AUTOSAR XML (schema 4-1-3)
standard types defined: boolean, sint8, uint16, uint32, uint8, boolean_CompuMethod, boolean_DataConstr, sint8_DataConstr, uint16_DataConstr, uint32_DataConstr, uint8_DataConstr
package /MICROSAR/Dem_swc/DataTypes
  5 x impl type:
    Dem_DebounceResetStatusType: compu {0=DEM_DEBOUNCE_STATUS_FREEZE, 1=DEM_DEBOUNCE_STATUS_RESET}, range raw 0..255, implementation-data-type=ImplementationDataTypes/uint8
    Dem_DTCFormatType: compu {0=DEM_DTC_FORMAT_OBD, 1=DEM_DTC_FORMAT_UDS, 2=DEM_DTC_FORMAT_J1939}, range raw 0..255, implementation-data-type=ImplementationDataTypes/uint8
    Dem_EventStatusType:
      compu {0=DEM_EVENT_STATUS_PASSED, 1=DEM_EVENT_STATUS_FAILED, 2=DEM_EVENT_STATUS_PREPASSED, 3=DEM_EVENT_STATUS_PREFAILED, 4=DEM_EVENT_STATUS_FDC_THRESHOLD_REACHED, 5=DEM_EVENT_STATUS_PASSED_CONDITIONS_NOT_FULFILLED, 6=DEM_EVENT_STATUS_FAILED_CONDITIONS_NOT_FULFILLED, 7=DEM_EVENT_STATUS_PREPASSED_CONDITIONS_NOT_FULFILLED, 8=DEM_EVENT_STATUS_PREFAILED_CONDITIONS_NOT_FULFILLED}
      range raw 0..255
      implementation-data-type=ImplementationDataTypes/uint8
    Dem_MaxDataValueType: category=ARRAY, sw-calibration-access=READ-ONLY
      element Dem_MaxDataValueTypeElement: array-size=4, array-size-semantics=FIXED-SIZE, implementation-data-type=ImplementationDataTypes/uint8
    Dem_UdsStatusByteType:
      compu {mask 1: 1=DEM_UDS_STATUS_TF (bit 0: TestFailed), mask 2: 2=DEM_UDS_STATUS_TFTOC (bit 1: TestFailedThisOperationCycle), mask 4: 4=DEM_UDS_STATUS_PDTC (bit 2: PendingDTC), mask 8: 8=DEM_UDS_STATUS_CDTC (bit 3: ConfirmedDTC), mask 16: 16=DEM_UDS_STATUS_TNCSLC (bit 4: TestNotCompletedSinceLastClear), mask 32: 32=DEM_UDS_STATUS_TFSLC (bit 5: TestFailedSinceLastClear), mask 64: 64=DEM_UDS_STATUS_TNCTOC (bit 6: TestNotCompletedThisOperationCycle), mask 128: 128=DEM_UDS_STATUS_WIR (bit 7: WarningIndicatorRequested)}
      range raw 0..255
      implementation-data-type=ImplementationDataTypes/uint8
package /MICROSAR/Dem_swc/Interfaces
  client server interface DiagnosticMonitor: is-service=true, service-kind=DIAGNOSTIC-EVENT-MANAGER
    11 x operation:
      GetDTCOfEvent: possible-error=[DEM_E_NO_DTC_AVAILABLE, DiagnosticMonitor/E_NOT_OK]
        arg DTCFormat: type=Dem_DTCFormatType, direction=IN, server-argument-impl-policy=USE-ARGUMENT-TYPE
        arg DTCOfEvent: type=ImplementationDataTypes/uint32, direction=OUT, server-argument-impl-policy=USE-ARGUMENT-TYPE
      GetEventExtendedDataRecordEx: possible-error=[DEM_BUFFER_TOO_SMALL, DEM_NO_SUCH_ELEMENT, DiagnosticMonitor/E_NOT_OK]
        arg RecordNumber: type=ImplementationDataTypes/uint8, direction=IN, server-argument-impl-policy=USE-ARGUMENT-TYPE
        arg DestBuffer: type=Dem_MaxDataValueType, direction=OUT, server-argument-impl-policy=USE-ARGUMENT-TYPE
        arg BufSize: type=ImplementationDataTypes/uint16, direction=INOUT, server-argument-impl-policy=USE-ARGUMENT-TYPE
      GetEventFailed: possible-error=DiagnosticMonitor/E_NOT_OK
        arg EventFailed: type=ImplementationDataTypes/boolean, direction=OUT, server-argument-impl-policy=USE-ARGUMENT-TYPE
      GetEventFreezeFrameDataEx: possible-error=[DEM_BUFFER_TOO_SMALL, DEM_NO_SUCH_ELEMENT, DiagnosticMonitor/E_NOT_OK]
        4 x arg, all with server-argument-impl-policy=USE-ARGUMENT-TYPE:
          RecordNumber: type=ImplementationDataTypes/uint8, direction=IN
          DataId: type=ImplementationDataTypes/uint16, direction=IN
          DestBuffer: type=Dem_MaxDataValueType, direction=OUT
          BufSize: type=ImplementationDataTypes/uint16, direction=INOUT
      GetEventStatus: possible-error=DiagnosticMonitor/E_NOT_OK
        arg UDSStatusByte: type=Dem_UdsStatusByteType, direction=OUT, server-argument-impl-policy=USE-ARGUMENT-TYPE
      GetEventTested: possible-error=DiagnosticMonitor/E_NOT_OK
        arg EventTested: type=ImplementationDataTypes/boolean, direction=OUT, server-argument-impl-policy=USE-ARGUMENT-TYPE
      GetEventUdsStatus: possible-error=DiagnosticMonitor/E_NOT_OK
        arg UDSStatusByte: type=Dem_UdsStatusByteType, direction=OUT, server-argument-impl-policy=USE-ARGUMENT-TYPE
      GetFaultDetectionCounter: possible-error=[DEM_E_NO_FDC_AVAILABLE, DiagnosticMonitor/E_NOT_OK]
        arg FaultDetectionCounter: type=sint8, direction=OUT, server-argument-impl-policy=USE-ARGUMENT-TYPE
      ResetEventDebounceStatus: possible-error=DiagnosticMonitor/E_NOT_OK
        arg DebounceResetStatus: type=Dem_DebounceResetStatusType, direction=IN, server-argument-impl-policy=USE-ARGUMENT-TYPE
      ResetEventStatus: possible-error=DiagnosticMonitor/E_NOT_OK
      SetEventStatus: possible-error=DiagnosticMonitor/E_NOT_OK
        arg EventStatus: type=Dem_EventStatusType, direction=IN, server-argument-impl-policy=USE-ARGUMENT-TYPE
    5 x error:
      DEM_BUFFER_TOO_SMALL: error-code=21
      DEM_E_NO_DTC_AVAILABLE: error-code=10
      DEM_E_NO_FDC_AVAILABLE: error-code=14
      DEM_NO_SUCH_ELEMENT: error-code=48
      E_NOT_OK: error-code=1
package /UAES/ASW/CompuMethods
  compu method CM_boolean: 0=FALSE, 1=TRUE
package /UAES/ASW/DataConstrs
  range DC_boolean: raw 0..1
  range DC_uint16: raw 0..65535
  range DC_uint32: raw 0..4294967295
  range DC_uint8: raw 0..255
package /UAES/ASW/DataTypeMappingSets
  data type mapping set DTMS_ElecDoorHndl_DD
package /UAES/ASW/PortInterfaces
  4 x client server interface:
    IoHwAb_HbrModCtrl
      operation Hbr_SetMod: possible-error=IoHwAb_HbrModCtrl/E_NOT_OK
        arg id_u16: type=ImplementationDataTypes/uint16, direction=IN, server-argument-impl-policy=USE-ARGUMENT-TYPE
        arg mod_u8: type=ImplementationDataTypes/uint8, direction=IN, server-argument-impl-policy=USE-ARGUMENT-TYPE
      error E_NOT_OK: error-code=1
    IoHwAb_HbrPwm
      operation Hbr_SetDuty: possible-error=IoHwAb_HbrPwm/E_NOT_OK
        arg id_u16: type=ImplementationDataTypes/uint16, direction=IN, server-argument-impl-policy=USE-ARGUMENT-TYPE
        arg duty_u16: type=ImplementationDataTypes/uint16, direction=IN, server-argument-impl-policy=USE-ARGUMENT-TYPE
      operation Hbr_SetPerd: possible-error=IoHwAb_HbrPwm/E_NOT_OK
        arg id_u16: type=ImplementationDataTypes/uint16, direction=IN, server-argument-impl-policy=USE-ARGUMENT-TYPE
        arg perd_u32: type=ImplementationDataTypes/uint32, direction=IN, server-argument-impl-policy=USE-ARGUMENT-TYPE
      operation Hbr_SetPerdAndDuty: possible-error=IoHwAb_HbrPwm/E_NOT_OK
        arg id_u16: type=ImplementationDataTypes/uint16, direction=IN, server-argument-impl-policy=USE-ARGUMENT-TYPE
        arg perd_u32: type=ImplementationDataTypes/uint32, direction=IN, server-argument-impl-policy=USE-ARGUMENT-TYPE
        arg duty_u16: type=ImplementationDataTypes/uint16, direction=IN, server-argument-impl-policy=USE-ARGUMENT-TYPE
      error E_NOT_OK: error-code=1
    IoHwAb_IoDiagHbr
      operation Hbr_Get: possible-error=IoHwAb_IoDiagHbr/E_NOT_OK
        arg id_u16: type=ImplementationDataTypes/uint16, direction=IN, server-argument-impl-policy=USE-ARGUMENT-TYPE
        arg val_u32: type=ImplementationDataTypes/uint32, direction=OUT, server-argument-impl-policy=USE-ARGUMENT-TYPE
      error E_NOT_OK: error-code=1
    IoHwAb_IoSigDio
      operation Di_Get: possible-error=IoHwAb_IoSigDio/E_NOT_OK
        arg id_u16: type=ImplementationDataTypes/uint16, direction=IN, server-argument-impl-policy=USE-ARGUMENT-TYPE
        arg val_u8: type=ImplementationDataTypes/uint8, direction=OUT, server-argument-impl-policy=USE-ARGUMENT-TYPE
      operation Do_Set: possible-error=IoHwAb_IoSigDio/E_NOT_OK
        arg id_u16: type=ImplementationDataTypes/uint16, direction=IN, server-argument-impl-policy=USE-ARGUMENT-TYPE
        arg val_u8: type=ImplementationDataTypes/uint8, direction=IN, server-argument-impl-policy=USE-ARGUMENT-TYPE
      error E_NOT_OK: error-code=1
  24 x sender receiver interface:
    gASI_bFLDoorHSULockSw: invalidation-policy{data-element=gASI_bFLDoorHSULockSw/Val, handle-invalid=DONT-INVALIDATE}
      data Val: sw-calibration-access=READ-ONLY, type=ImplementationDataTypes/boolean
    gASI_bFLDoorHSUUnlockSw: invalidation-policy{data-element=gASI_bFLDoorHSUUnlockSw/Val, handle-invalid=DONT-INVALIDATE}
      data Val: sw-calibration-access=READ-ONLY, type=ImplementationDataTypes/boolean
    gASI_bFRDoorHSULockSw: invalidation-policy{data-element=gASI_bFRDoorHSULockSw/Val, handle-invalid=DONT-INVALIDATE}
      data Val: sw-calibration-access=READ-ONLY, type=ImplementationDataTypes/boolean
    gASI_bFRDoorHSUSw: invalidation-policy{data-element=gASI_bFRDoorHSUSw/Val, handle-invalid=DONT-INVALIDATE}
      data Val: sw-calibration-access=READ-ONLY, type=ImplementationDataTypes/boolean
    gASI_bFRDoorHSUUnlockSw: invalidation-policy{data-element=gASI_bFRDoorHSUUnlockSw/Val, handle-invalid=DONT-INVALIDATE}
      data Val: sw-calibration-access=READ-ONLY, type=ImplementationDataTypes/boolean
    gASI_bRLDoorHSULockSw: invalidation-policy{data-element=gASI_bRLDoorHSULockSw/Val, handle-invalid=DONT-INVALIDATE}
      data Val: sw-calibration-access=READ-ONLY, type=ImplementationDataTypes/boolean
    gASI_bRLDoorHSUUnlockSw: invalidation-policy{data-element=gASI_bRLDoorHSUUnlockSw/Val, handle-invalid=DONT-INVALIDATE}
      data Val: sw-calibration-access=READ-ONLY, type=ImplementationDataTypes/boolean
    gASI_bRRDoorHSULockSw: invalidation-policy{data-element=gASI_bRRDoorHSULockSw/Val, handle-invalid=DONT-INVALIDATE}
      data Val: sw-calibration-access=READ-ONLY, type=ImplementationDataTypes/boolean
    gASI_bRRDoorHSUUnlockSw: invalidation-policy{data-element=gASI_bRRDoorHSUUnlockSw/Val, handle-invalid=DONT-INVALIDATE}
      data Val: sw-calibration-access=READ-ONLY, type=ImplementationDataTypes/boolean
    gEDH_bFLHallSupplyOutput: invalidation-policy{data-element=gEDH_bFLHallSupplyOutput/Val, handle-invalid=DONT-INVALIDATE}
      data Val: sw-calibration-access=READ-ONLY, type=ImplementationDataTypes/boolean
    gEDH_bFRHallSupplyOutput: invalidation-policy{data-element=gEDH_bFRHallSupplyOutput/Val, handle-invalid=DONT-INVALIDATE}
      data Val: sw-calibration-access=READ-ONLY, type=ImplementationDataTypes/boolean
    gEDH_u8FLDoorHandleMotorOutput: invalidation-policy{data-element=gEDH_u8FLDoorHandleMotorOutput/Val, handle-invalid=DONT-INVALIDATE}
      data Val: sw-calibration-access=READ-ONLY, type=ImplementationDataTypes/uint8
    gEDH_u8FLDoorHandlePWMOutput: invalidation-policy{data-element=gEDH_u8FLDoorHandlePWMOutput/Val, handle-invalid=DONT-INVALIDATE}
      data Val: sw-calibration-access=READ-ONLY, type=ImplementationDataTypes/uint8
    gEDH_u8FRDoorHandleMotorOutput: invalidation-policy{data-element=gEDH_u8FRDoorHandleMotorOutput/Val, handle-invalid=DONT-INVALIDATE}
      data Val: sw-calibration-access=READ-ONLY, type=ImplementationDataTypes/uint8
    gEDH_u8FRDoorHandlePWMOutput: invalidation-policy{data-element=gEDH_u8FRDoorHandlePWMOutput/Val, handle-invalid=DONT-INVALIDATE}
      data Val: sw-calibration-access=READ-ONLY, type=ImplementationDataTypes/uint8
    gEDH_u8RLDoorHandleMotorOutput: invalidation-policy{data-element=gEDH_u8RLDoorHandleMotorOutput/Val, handle-invalid=DONT-INVALIDATE}
      data Val: sw-calibration-access=READ-ONLY, type=ImplementationDataTypes/uint8
    gEDH_u8RLDoorHandlePWMOutput: invalidation-policy{data-element=gEDH_u8RLDoorHandlePWMOutput/Val, handle-invalid=DONT-INVALIDATE}
      data Val: sw-calibration-access=READ-ONLY, type=ImplementationDataTypes/uint8
    gEDH_u8RRDoorHandleMotorOutput: invalidation-policy{data-element=gEDH_u8RRDoorHandleMotorOutput/Val, handle-invalid=DONT-INVALIDATE}
      data Val: sw-calibration-access=READ-ONLY, type=ImplementationDataTypes/uint8
    gEDH_u8RRDoorHandlePWMOutput: invalidation-policy{data-element=gEDH_u8RRDoorHandlePWMOutput/Val, handle-invalid=DONT-INVALIDATE}
      data Val: sw-calibration-access=READ-ONLY, type=ImplementationDataTypes/uint8
    gElecDoorHndl_u8FLDoorHndlMotorPs: invalidation-policy{data-element=gElecDoorHndl_u8FLDoorHndlMotorPs/Val, handle-invalid=DONT-INVALIDATE}
      data Val: sw-calibration-access=READ-ONLY, type=ImplementationDataTypes/uint8
    gElecDoorHndl_u8FRDoorHndlMotorPs: invalidation-policy{data-element=gElecDoorHndl_u8FRDoorHndlMotorPs/Val, handle-invalid=DONT-INVALIDATE}
      data Val: sw-calibration-access=READ-ONLY, type=ImplementationDataTypes/uint8
    gElecDoorHndl_u8RLDoorHndlMotorPs: invalidation-policy{data-element=gElecDoorHndl_u8RLDoorHndlMotorPs/Val, handle-invalid=DONT-INVALIDATE}
      data Val: sw-calibration-access=READ-ONLY, type=ImplementationDataTypes/uint8
    gElecDoorHndl_u8RRDoorHndlMotorPs: invalidation-policy{data-element=gElecDoorHndl_u8RRDoorHndlMotorPs/Val, handle-invalid=DONT-INVALIDATE}
      data Val: sw-calibration-access=READ-ONLY, type=ImplementationDataTypes/uint8
    gLock_u8DiagEnbCnd: invalidation-policy{data-element=gLock_u8DiagEnbCnd/Val, handle-invalid=DONT-INVALIDATE}
      data Val: sw-calibration-access=READ-ONLY, type=ImplementationDataTypes/uint8
package /UAES/ASW/SwComponentTypes
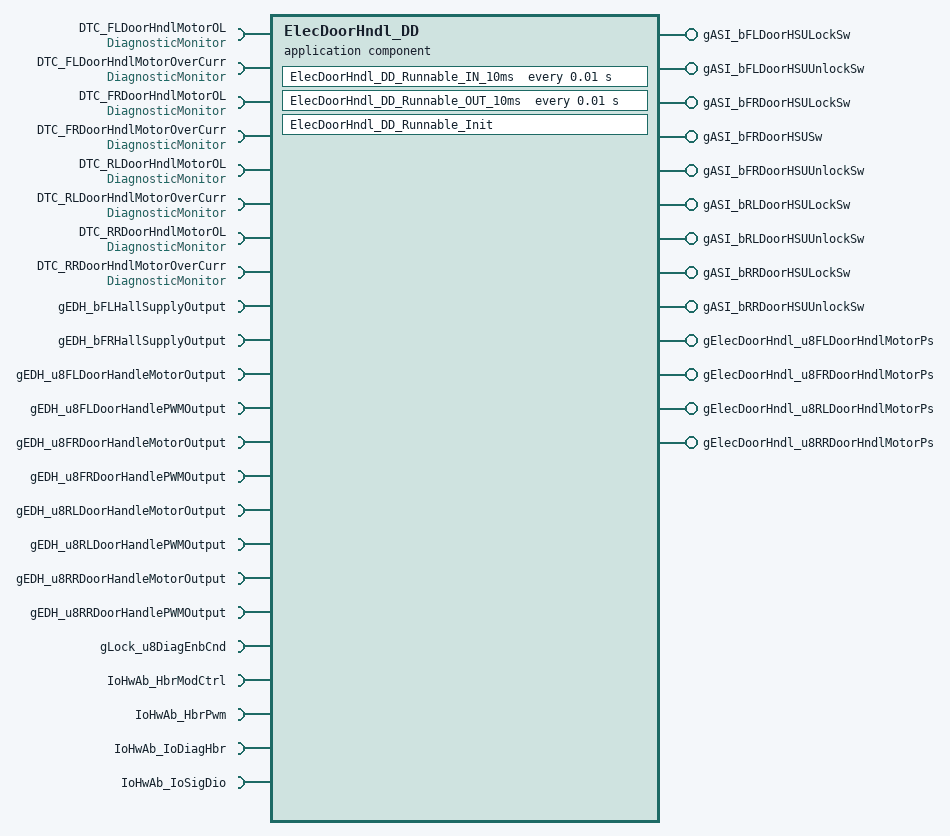
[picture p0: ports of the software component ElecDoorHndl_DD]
  application sw component type ElecDoorHndl_DD
    13 x provide port:
      gASI_bFLDoorHSULockSw: nonqueued-sender-com-spec{data-element=gASI_bFLDoorHSULockSw/Val, init-value=0}, provided-interface=gASI_bFLDoorHSULockSw
      gASI_bFLDoorHSUUnlockSw: nonqueued-sender-com-spec{data-element=gASI_bFLDoorHSUUnlockSw/Val, init-value=0}, provided-interface=gASI_bFLDoorHSUUnlockSw
      gASI_bFRDoorHSULockSw: nonqueued-sender-com-spec{data-element=gASI_bFRDoorHSULockSw/Val, init-value=0}, provided-interface=gASI_bFRDoorHSULockSw
      gASI_bFRDoorHSUSw: nonqueued-sender-com-spec{data-element=gASI_bFRDoorHSUSw/Val, init-value=0}, provided-interface=gASI_bFRDoorHSUSw
      gASI_bFRDoorHSUUnlockSw: nonqueued-sender-com-spec{data-element=gASI_bFRDoorHSUUnlockSw/Val, init-value=0}, provided-interface=gASI_bFRDoorHSUUnlockSw
      gASI_bRLDoorHSULockSw: nonqueued-sender-com-spec{data-element=gASI_bRLDoorHSULockSw/Val, init-value=0}, provided-interface=gASI_bRLDoorHSULockSw
      gASI_bRLDoorHSUUnlockSw: nonqueued-sender-com-spec{data-element=gASI_bRLDoorHSUUnlockSw/Val, init-value=0}, provided-interface=gASI_bRLDoorHSUUnlockSw
      gASI_bRRDoorHSULockSw: nonqueued-sender-com-spec{data-element=gASI_bRRDoorHSULockSw/Val, init-value=0}, provided-interface=gASI_bRRDoorHSULockSw
      gASI_bRRDoorHSUUnlockSw: nonqueued-sender-com-spec{data-element=gASI_bRRDoorHSUUnlockSw/Val, init-value=0}, provided-interface=gASI_bRRDoorHSUUnlockSw
      gElecDoorHndl_u8FLDoorHndlMotorPs: nonqueued-sender-com-spec{data-element=gElecDoorHndl_u8FLDoorHndlMotorPs/Val, init-value=0}, provided-interface=gElecDoorHndl_u8FLDoorHndlMotorPs
      gElecDoorHndl_u8FRDoorHndlMotorPs: nonqueued-sender-com-spec{data-element=gElecDoorHndl_u8FRDoorHndlMotorPs/Val, init-value=0}, provided-interface=gElecDoorHndl_u8FRDoorHndlMotorPs
      gElecDoorHndl_u8RLDoorHndlMotorPs: nonqueued-sender-com-spec{data-element=gElecDoorHndl_u8RLDoorHndlMotorPs/Val, init-value=0}, provided-interface=gElecDoorHndl_u8RLDoorHndlMotorPs
      gElecDoorHndl_u8RRDoorHndlMotorPs: nonqueued-sender-com-spec{data-element=gElecDoorHndl_u8RRDoorHndlMotorPs/Val, init-value=0}, provided-interface=gElecDoorHndl_u8RRDoorHndlMotorPs
    23 x require port:
      DTC_FLDoorHndlMotorOL: required-interface=DiagnosticMonitor
        required-com-specs:
          GetDTCOfEvent
          GetEventExtendedDataRecordEx
          GetEventFailed
          GetEventFreezeFrameDataEx
          GetEventStatus
          GetEventTested
          GetEventUdsStatus
          GetFaultDetectionCounter
          ResetEventDebounceStatus
          ResetEventStatus
          SetEventStatus
      DTC_FLDoorHndlMotorOverCurr: required-interface=DiagnosticMonitor
        required-com-specs:
          GetDTCOfEvent
          GetEventExtendedDataRecordEx
          GetEventFailed
          GetEventFreezeFrameDataEx
          GetEventStatus
          GetEventTested
          GetEventUdsStatus
          GetFaultDetectionCounter
          ResetEventDebounceStatus
          ResetEventStatus
          SetEventStatus
      DTC_FRDoorHndlMotorOL: required-interface=DiagnosticMonitor
        required-com-specs:
          GetDTCOfEvent
          GetEventExtendedDataRecordEx
          GetEventFailed
          GetEventFreezeFrameDataEx
          GetEventStatus
          GetEventTested
          GetEventUdsStatus
          GetFaultDetectionCounter
          ResetEventDebounceStatus
          ResetEventStatus
          SetEventStatus
      DTC_FRDoorHndlMotorOverCurr: required-interface=DiagnosticMonitor
        required-com-specs:
          GetDTCOfEvent
          GetEventExtendedDataRecordEx
          GetEventFailed
          GetEventFreezeFrameDataEx
          GetEventStatus
          GetEventTested
          GetEventUdsStatus
          GetFaultDetectionCounter
          ResetEventDebounceStatus
          ResetEventStatus
          SetEventStatus
      DTC_RLDoorHndlMotorOL: required-interface=DiagnosticMonitor
        required-com-specs:
          GetDTCOfEvent
          GetEventExtendedDataRecordEx
          GetEventFailed
          GetEventFreezeFrameDataEx
          GetEventStatus
          GetEventTested
          GetEventUdsStatus
          GetFaultDetectionCounter
          ResetEventDebounceStatus
          ResetEventStatus
          SetEventStatus
      DTC_RLDoorHndlMotorOverCurr: required-interface=DiagnosticMonitor
        required-com-specs:
          GetDTCOfEvent
          GetEventExtendedDataRecordEx
          GetEventFailed
          GetEventFreezeFrameDataEx
          GetEventStatus
          GetEventTested
          GetEventUdsStatus
          GetFaultDetectionCounter
          ResetEventDebounceStatus
          ResetEventStatus
          SetEventStatus
      DTC_RRDoorHndlMotorOL: required-interface=DiagnosticMonitor
        required-com-specs:
          GetDTCOfEvent
          GetEventExtendedDataRecordEx
          GetEventFailed
          GetEventFreezeFrameDataEx
          GetEventStatus
          GetEventTested
          GetEventUdsStatus
          GetFaultDetectionCounter
          ResetEventDebounceStatus
          ResetEventStatus
          SetEventStatus
      DTC_RRDoorHndlMotorOverCurr: required-interface=DiagnosticMonitor
        required-com-specs:
          GetDTCOfEvent
          GetEventExtendedDataRecordEx
          GetEventFailed
          GetEventFreezeFrameDataEx
          GetEventStatus
          GetEventTested
          GetEventUdsStatus
          GetFaultDetectionCounter
          ResetEventDebounceStatus
          ResetEventStatus
          SetEventStatus
      gEDH_bFLHallSupplyOutput: nonqueued-receiver-com-spec{data-element=gEDH_bFLHallSupplyOutput/Val, filter=data-filter-type=ALWAYS, init-value=0}, required-interface=gEDH_bFLHallSupplyOutput
      gEDH_bFRHallSupplyOutput: nonqueued-receiver-com-spec{data-element=gEDH_bFRHallSupplyOutput/Val, filter=data-filter-type=ALWAYS, init-value=0}, required-interface=gEDH_bFRHallSupplyOutput
      gEDH_u8FLDoorHandleMotorOutput: nonqueued-receiver-com-spec{data-element=gEDH_u8FLDoorHandleMotorOutput/Val, filter=data-filter-type=ALWAYS, init-value=0}, required-interface=gEDH_u8FLDoorHandleMotorOutput
      gEDH_u8FLDoorHandlePWMOutput: nonqueued-receiver-com-spec{data-element=gEDH_u8FLDoorHandlePWMOutput/Val, filter=data-filter-type=ALWAYS, init-value=0}, required-interface=gEDH_u8FLDoorHandlePWMOutput
      gEDH_u8FRDoorHandleMotorOutput: nonqueued-receiver-com-spec{data-element=gEDH_u8FRDoorHandleMotorOutput/Val, filter=data-filter-type=ALWAYS, init-value=0}, required-interface=gEDH_u8FRDoorHandleMotorOutput
      gEDH_u8FRDoorHandlePWMOutput: nonqueued-receiver-com-spec{data-element=gEDH_u8FRDoorHandlePWMOutput/Val, filter=data-filter-type=ALWAYS, init-value=0}, required-interface=gEDH_u8FRDoorHandlePWMOutput
      gEDH_u8RLDoorHandleMotorOutput: nonqueued-receiver-com-spec{data-element=gEDH_u8RLDoorHandleMotorOutput/Val, filter=data-filter-type=ALWAYS, init-value=0}, required-interface=gEDH_u8RLDoorHandleMotorOutput
      gEDH_u8RLDoorHandlePWMOutput: nonqueued-receiver-com-spec{data-element=gEDH_u8RLDoorHandlePWMOutput/Val, filter=data-filter-type=ALWAYS, init-value=0}, required-interface=gEDH_u8RLDoorHandlePWMOutput
      gEDH_u8RRDoorHandleMotorOutput: nonqueued-receiver-com-spec{data-element=gEDH_u8RRDoorHandleMotorOutput/Val, filter=data-filter-type=ALWAYS, init-value=0}, required-interface=gEDH_u8RRDoorHandleMotorOutput
      gEDH_u8RRDoorHandlePWMOutput: nonqueued-receiver-com-spec{data-element=gEDH_u8RRDoorHandlePWMOutput/Val, filter=data-filter-type=ALWAYS, init-value=0}, required-interface=gEDH_u8RRDoorHandlePWMOutput
      gLock_u8DiagEnbCnd: nonqueued-receiver-com-spec{data-element=gLock_u8DiagEnbCnd/Val, filter=data-filter-type=ALWAYS, init-value=0}, required-interface=gLock_u8DiagEnbCnd
      IoHwAb_HbrModCtrl: client-com-spec=Hbr_SetMod, required-interface=IoHwAb_HbrModCtrl
      IoHwAb_HbrPwm: required-com-specs=[Hbr_SetDuty, Hbr_SetPerd, Hbr_SetPerdAndDuty], required-interface=IoHwAb_HbrPwm
      IoHwAb_IoDiagHbr: client-com-spec=Hbr_Get, required-interface=IoHwAb_IoDiagHbr
      IoHwAb_IoSigDio: required-com-specs=[Di_Get, Do_Set], required-interface=IoHwAb_IoSigDio
    behavior ElecDoorHndl_DD_InternalBehavior: data-type-mapping=DTMS_ElecDoorHndl_DD
      timing event TMT_ElecDoorHndl_DD_Runnable_IN_10ms: start-on-event=ElecDoorHndl_DD_Runnable_IN_10ms, period=0.01
      init event ElecDoorHndl_DD_InitEvent: start-on-event=ElecDoorHndl_DD_Runnable_Init
      timing event TMT_ElecDoorHndl_DD_Runnable_OUT_10ms: start-on-event=ElecDoorHndl_DD_Runnable_OUT_10ms, period=0.01
      runnable ElecDoorHndl_DD_Runnable_IN_10ms
        data-send-points:
          9 x access:
            OUT_gASI_bFLDoorHSULockSw_Val: accessed-variable=gASI_bFLDoorHSULockSw.Val
            OUT_gASI_bFLDoorHSUUnlockSw_Val: accessed-variable=gASI_bFLDoorHSUUnlockSw.Val
            OUT_gASI_bFRDoorHSULockSw_Val: accessed-variable=gASI_bFRDoorHSULockSw.Val
            OUT_gASI_bFRDoorHSUSw_Val: accessed-variable=gASI_bFRDoorHSUSw.Val
            OUT_gASI_bFRDoorHSUUnlockSw_Val: accessed-variable=gASI_bFRDoorHSUUnlockSw.Val
            OUT_gASI_bRLDoorHSULockSw_Val: accessed-variable=gASI_bRLDoorHSULockSw.Val
            OUT_gASI_bRLDoorHSUUnlockSw_Val: accessed-variable=gASI_bRLDoorHSUUnlockSw.Val
            OUT_gASI_bRRDoorHSULockSw_Val: accessed-variable=gASI_bRRDoorHSULockSw.Val
            OUT_gASI_bRRDoorHSUUnlockSw_Val: accessed-variable=gASI_bRRDoorHSUUnlockSw.Val
        sync call SC_IoHwAb_IoSigDio_Di_Get: operation=IoHwAb_IoSigDio.Di_Get, timeout=0
      runnable ElecDoorHndl_DD_Runnable_Init
      runnable ElecDoorHndl_DD_Runnable_OUT_10ms
        data-receive-point-by-arguments:
          11 x access:
            IN_gEDH_bFLHallSupplyOutput_Val: accessed-variable=gEDH_bFLHallSupplyOutput.Val
            IN_gEDH_bFRHallSupplyOutput_Val: accessed-variable=gEDH_bFRHallSupplyOutput.Val
            IN_gEDH_u8FLDoorHandleMotorOutput_Val: accessed-variable=gEDH_u8FLDoorHandleMotorOutput.Val
            IN_gEDH_u8FLDoorHandlePWMOutput_Val: accessed-variable=gEDH_u8FLDoorHandlePWMOutput.Val
            IN_gEDH_u8FRDoorHandleMotorOutput_Val: accessed-variable=gEDH_u8FRDoorHandleMotorOutput.Val
            IN_gEDH_u8FRDoorHandlePWMOutput_Val: accessed-variable=gEDH_u8FRDoorHandlePWMOutput.Val
            IN_gEDH_u8RLDoorHandleMotorOutput_Val: accessed-variable=gEDH_u8RLDoorHandleMotorOutput.Val
            IN_gEDH_u8RLDoorHandlePWMOutput_Val: accessed-variable=gEDH_u8RLDoorHandlePWMOutput.Val
            IN_gEDH_u8RRDoorHandleMotorOutput_Val: accessed-variable=gEDH_u8RRDoorHandleMotorOutput.Val
            IN_gEDH_u8RRDoorHandlePWMOutput_Val: accessed-variable=gEDH_u8RRDoorHandlePWMOutput.Val
            REC_gLock_u8DiagEnbCnd_Val: accessed-variable=gLock_u8DiagEnbCnd.Val
        data-send-points:
          4 x access:
            SEND_gElecDoorHndl_u8FLDoorHndlMotorPs_Val: accessed-variable=gElecDoorHndl_u8FLDoorHndlMotorPs.Val
            SEND_gElecDoorHndl_u8FRDoorHndlMotorPs_Val: accessed-variable=gElecDoorHndl_u8FRDoorHndlMotorPs.Val
            SEND_gElecDoorHndl_u8RLDoorHndlMotorPs_Val: accessed-variable=gElecDoorHndl_u8RLDoorHndlMotorPs.Val
            SEND_gElecDoorHndl_u8RRDoorHndlMotorPs_Val: accessed-variable=gElecDoorHndl_u8RRDoorHndlMotorPs.Val
        28 x sync call:
          SC_DTC_FLDoorHndlMotorOL_GetEventFailed: operation=DTC_FLDoorHndlMotorOL.GetEventFailed, timeout=1E-06
          SC_DTC_FLDoorHndlMotorOL_ResetEventDebounceStatus: operation=DTC_FLDoorHndlMotorOL.ResetEventDebounceStatus, timeout=1E-06
          SC_DTC_FLDoorHndlMotorOL_SetEventStatus: operation=DTC_FLDoorHndlMotorOL.SetEventStatus, timeout=1E-06
          SC_DTC_FLDoorHndlMotorOverCurr_GetEventFailed: operation=DTC_FLDoorHndlMotorOverCurr.GetEventFailed, timeout=1E-06
          SC_DTC_FLDoorHndlMotorOverCurr_ResetEventDebounceStatus: operation=DTC_FLDoorHndlMotorOverCurr.ResetEventDebounceStatus, timeout=1E-06
          SC_DTC_FLDoorHndlMotorOverCurr_SetEventStatus: operation=DTC_FLDoorHndlMotorOverCurr.SetEventStatus, timeout=1E-06
          SC_DTC_FRDoorHndlMotorOL_GetEventFailed: operation=DTC_FRDoorHndlMotorOL.GetEventFailed, timeout=1E-06
          SC_DTC_FRDoorHndlMotorOL_ResetEventDebounceStatus: operation=DTC_FRDoorHndlMotorOL.ResetEventDebounceStatus, timeout=1E-06
          SC_DTC_FRDoorHndlMotorOL_SetEventStatus: operation=DTC_FRDoorHndlMotorOL.SetEventStatus, timeout=1E-06
          SC_DTC_FRDoorHndlMotorOverCurr_GetEventFailed: operation=DTC_FRDoorHndlMotorOverCurr.GetEventFailed, timeout=1E-06
          SC_DTC_FRDoorHndlMotorOverCurr_ResetEventDebounceStatus: operation=DTC_FRDoorHndlMotorOverCurr.ResetEventDebounceStatus, timeout=1E-06
          SC_DTC_FRDoorHndlMotorOverCurr_SetEventStatus: operation=DTC_FRDoorHndlMotorOverCurr.SetEventStatus, timeout=1E-06
          SC_DTC_RLDoorHndlMotorOL_GetEventFailed: operation=DTC_RLDoorHndlMotorOL.GetEventFailed, timeout=1E-06
          SC_DTC_RLDoorHndlMotorOL_ResetEventDebounceStatus: operation=DTC_RLDoorHndlMotorOL.ResetEventDebounceStatus, timeout=1E-06
          SC_DTC_RLDoorHndlMotorOL_SetEventStatus: operation=DTC_RLDoorHndlMotorOL.SetEventStatus, timeout=1E-06
          SC_DTC_RLDoorHndlMotorOverCurr_GetEventFailed: operation=DTC_RLDoorHndlMotorOverCurr.GetEventFailed, timeout=1E-06
          SC_DTC_RLDoorHndlMotorOverCurr_ResetEventDebounceStatus: operation=DTC_RLDoorHndlMotorOverCurr.ResetEventDebounceStatus, timeout=1E-06
          SC_DTC_RLDoorHndlMotorOverCurr_SetEventStatus: operation=DTC_RLDoorHndlMotorOverCurr.SetEventStatus, timeout=1E-06
          SC_DTC_RRDoorHndlMotorOL_GetEventFailed: operation=DTC_RRDoorHndlMotorOL.GetEventFailed, timeout=1E-06
          SC_DTC_RRDoorHndlMotorOL_ResetEventDebounceStatus: operation=DTC_RRDoorHndlMotorOL.ResetEventDebounceStatus, timeout=1E-06
          SC_DTC_RRDoorHndlMotorOL_SetEventStatus: operation=DTC_RRDoorHndlMotorOL.SetEventStatus, timeout=1E-06
          SC_DTC_RRDoorHndlMotorOverCurr_GetEventFailed: operation=DTC_RRDoorHndlMotorOverCurr.GetEventFailed, timeout=1E-06
          SC_DTC_RRDoorHndlMotorOverCurr_ResetEventDebounceStatus: operation=DTC_RRDoorHndlMotorOverCurr.ResetEventDebounceStatus, timeout=1E-06
          SC_DTC_RRDoorHndlMotorOverCurr_SetEventStatus: operation=DTC_RRDoorHndlMotorOverCurr.SetEventStatus, timeout=1E-06
          SC_IoHwAb_HbrModCtrl_Hbr_SetMod: operation=IoHwAb_HbrModCtrl.Hbr_SetMod, timeout=0
          SC_IoHwAb_HbrPwm_Hbr_SetDuty: operation=IoHwAb_HbrPwm.Hbr_SetDuty, timeout=0
          SC_IoHwAb_IoDiagHbr_Hbr_Get: operation=IoHwAb_IoDiagHbr.Hbr_Get, timeout=0
          SC_IoHwAb_IoSigDio_Do_Set: operation=IoHwAb_IoSigDio.Do_Set, timeout=0
  swc implementation Implementation_ElecDoorHndl_DD: behavior=ElecDoorHndl_DD_InternalBehavior
    code-descriptors:
      code Default: artifact-descriptors=autosar-engineering-object={short-label=Default, category=SWSRC}
package /UAES/ASW/Units
  unit NoUnit: factor-si-to-unit=1, offset-si-to-unit=0
